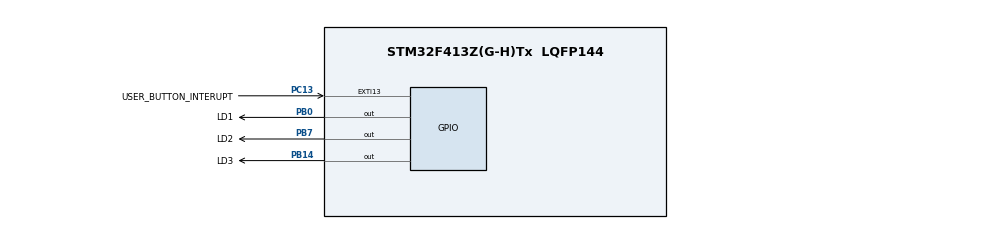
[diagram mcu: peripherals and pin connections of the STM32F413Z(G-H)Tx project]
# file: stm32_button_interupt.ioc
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Mcu.Family=STM32F4
Mcu.Name=STM32F413Z(G-H)Tx
Mcu.Package=LQFP144
NVIC.EXTI15_10_IRQn=true\:0\:0\:false\:false\:true\:true\:true\:true
NVIC.PriorityGroup=NVIC_PRIORITYGROUP_4
PB0.GPIO_Label=LD1
PB0.Signal=GPIO_Output
PB14.GPIO_Label=LD3
PB14.Signal=GPIO_Output
PB7.GPIO_Label=LD2
PB7.Signal=GPIO_Output
PC13.GPIO_Label=USER_BUTTON_INTERUPT
PC13.Signal=GPXTI13
ProjectManager.HeapSize=0x200
ProjectManager.StackSize=0x400
ProjectManager.TargetToolchain=STM32CubeIDE
RCC.CortexFreq_Value=16000000
RCC.USBFreq_Value=96000000
RCC.VCOOutputFreq_Value=192000000
board=custom

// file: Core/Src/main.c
/* USER CODE BEGIN Header */
/**
  ******************************************************************************
  * @file           : main.c
  * @brief          : Main program body
  ******************************************************************************
  * @attention
  *
  * Copyright (c) 2026 STMicroelectronics.
  * All rights reserved.
  *
  * This software is licensed under terms that can be found in the LICENSE file
  * in the root directory of this software component.
  * If no LICENSE file comes with this software, it is provided AS-IS.
  *
  ******************************************************************************
  */
/* USER CODE END Header */
#include "main.h"

/* USER CODE BEGIN PD */
volatile uint8_t counter=0;
volatile uint32_t last_interrupt_time = 0;
/* USER CODE END PD */

void SystemClock_Config(void);
static void MX_GPIO_Init(void);

int main(void)
{

  /* MCU Configuration--------------------------------------------------------*/

  /* Reset of all peripherals, Initializes the Flash interface and the Systick. */
  HAL_Init();

  /* Configure the system clock */
  SystemClock_Config();

  /* Initialize all configured peripherals */
  MX_GPIO_Init();

  /* Infinite loop */
  while (1)
  {

  }
}

void SystemClock_Config(void)
{
  RCC_OscInitTypeDef RCC_OscInitStruct = {0};
  RCC_ClkInitTypeDef RCC_ClkInitStruct = {0};

  /** Configure the main internal regulator output voltage
  */
  __HAL_RCC_PWR_CLK_ENABLE();
  __HAL_PWR_VOLTAGESCALING_CONFIG(PWR_REGULATOR_VOLTAGE_SCALE1);

  /** Initializes the RCC Oscillators according to the specified parameters
  * in the RCC_OscInitTypeDef structure.
  */
  RCC_OscInitStruct.OscillatorType = RCC_OSCILLATORTYPE_HSI;
  RCC_OscInitStruct.HSIState = RCC_HSI_ON;
  RCC_OscInitStruct.HSICalibrationValue = RCC_HSICALIBRATION_DEFAULT;
  RCC_OscInitStruct.PLL.PLLState = RCC_PLL_NONE;
  if (HAL_RCC_OscConfig(&RCC_OscInitStruct) != HAL_OK)
  {
    Error_Handler();
  }

  /** Initializes the CPU, AHB and APB buses clocks
  */
  RCC_ClkInitStruct.ClockType = RCC_CLOCKTYPE_HCLK|RCC_CLOCKTYPE_SYSCLK
                              |RCC_CLOCKTYPE_PCLK1|RCC_CLOCKTYPE_PCLK2;
  RCC_ClkInitStruct.SYSCLKSource = RCC_SYSCLKSOURCE_HSI;
  RCC_ClkInitStruct.AHBCLKDivider = RCC_SYSCLK_DIV1;
  RCC_ClkInitStruct.APB1CLKDivider = RCC_HCLK_DIV1;
  RCC_ClkInitStruct.APB2CLKDivider = RCC_HCLK_DIV1;

  if (HAL_RCC_ClockConfig(&RCC_ClkInitStruct, FLASH_LATENCY_0) != HAL_OK)
  {
    Error_Handler();
  }
}

static void MX_GPIO_Init(void)
{
  GPIO_InitTypeDef GPIO_InitStruct = {0};

  /* GPIO Ports Clock Enable */
  __HAL_RCC_GPIOC_CLK_ENABLE();
  __HAL_RCC_GPIOB_CLK_ENABLE();

  /*Configure GPIO pin Output Level */
  HAL_GPIO_WritePin(GPIOB, LD1_Pin|LD3_Pin|LD2_Pin, GPIO_PIN_RESET);

  /*Configure GPIO pin : USER_BUTTON_INTERUPT_Pin */
  GPIO_InitStruct.Pin = USER_BUTTON_INTERUPT_Pin;
  GPIO_InitStruct.Mode = GPIO_MODE_IT_RISING;
  GPIO_InitStruct.Pull = GPIO_NOPULL;
  HAL_GPIO_Init(USER_BUTTON_INTERUPT_GPIO_Port, &GPIO_InitStruct);

  /*Configure GPIO pins : LD1_Pin LD3_Pin LD2_Pin */
  GPIO_InitStruct.Pin = LD1_Pin|LD3_Pin|LD2_Pin;
  GPIO_InitStruct.Mode = GPIO_MODE_OUTPUT_PP;
  GPIO_InitStruct.Pull = GPIO_NOPULL;
  GPIO_InitStruct.Speed = GPIO_SPEED_FREQ_LOW;
  HAL_GPIO_Init(GPIOB, &GPIO_InitStruct);

  /* EXTI interrupt init*/
  HAL_NVIC_SetPriority(EXTI15_10_IRQn, 0, 0);
  HAL_NVIC_EnableIRQ(EXTI15_10_IRQn);

}

void Error_Handler(void)
{
  __disable_irq();
  while (1)
  {
  }
}
